AUTOSAR XML (schema 4-0-3)
package /ComponentTypes
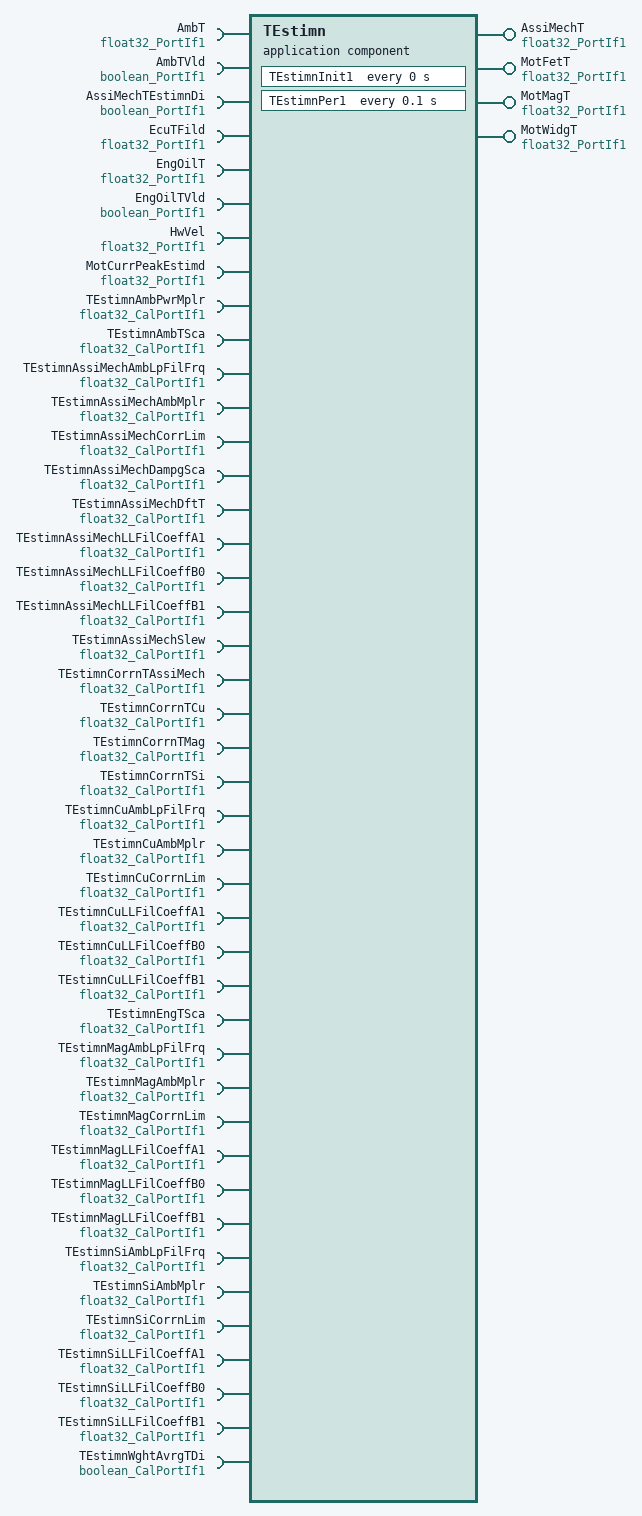
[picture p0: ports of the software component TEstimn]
  application sw component type TEstimn
    4 x provide port, all with nonqueued-sender-com-spec{data-element=Val, init-value=25}, provided-interface=float32_PortIf1:
      AssiMechT
      MotFetT
      MotMagT
      MotWidgT
    43 x require port:
      AmbT: nonqueued-receiver-com-spec{data-element=Val, filter=data-filter-type=ALWAYS, init-value=0}, required-interface=float32_PortIf1
      AmbTVld: nonqueued-receiver-com-spec{data-element=Logl, filter=data-filter-type=ALWAYS, init-value=0}, required-interface=boolean_PortIf1
      AssiMechTEstimnDi: nonqueued-receiver-com-spec{data-element=Logl, filter=data-filter-type=ALWAYS, init-value=0}, required-interface=boolean_PortIf1
      EcuTFild: nonqueued-receiver-com-spec{data-element=Val, filter=data-filter-type=ALWAYS, init-value=25}, required-interface=float32_PortIf1
      EngOilT: nonqueued-receiver-com-spec{data-element=Val, filter=data-filter-type=ALWAYS, init-value=0}, required-interface=float32_PortIf1
      EngOilTVld: nonqueued-receiver-com-spec{data-element=Logl, filter=data-filter-type=ALWAYS, init-value=0}, required-interface=boolean_PortIf1
      HwVel: nonqueued-receiver-com-spec{data-element=Val, filter=data-filter-type=ALWAYS, init-value=0}, required-interface=float32_PortIf1
      MotCurrPeakEstimd: nonqueued-receiver-com-spec{data-element=Val, filter=data-filter-type=ALWAYS, init-value=0}, required-interface=float32_PortIf1
      TEstimnAmbPwrMplr: parameter-require-com-spec{init-value=0.01, parameter=Val}, required-interface=float32_CalPortIf1
      TEstimnAmbTSca: parameter-require-com-spec{init-value=0.9, parameter=Val}, required-interface=float32_CalPortIf1
      TEstimnAssiMechAmbLpFilFrq: parameter-require-com-spec{init-value=0.024, parameter=Val}, required-interface=float32_CalPortIf1
      TEstimnAssiMechAmbMplr: parameter-require-com-spec{init-value=0.01, parameter=Val}, required-interface=float32_CalPortIf1
      TEstimnAssiMechCorrLim: parameter-require-com-spec{init-value=60, parameter=Val}, required-interface=float32_CalPortIf1
      TEstimnAssiMechDampgSca: parameter-require-com-spec{init-value=0.0001, parameter=Val}, required-interface=float32_CalPortIf1
      TEstimnAssiMechDftT: parameter-require-com-spec{init-value=50, parameter=Val}, required-interface=float32_CalPortIf1
      TEstimnAssiMechLLFilCoeffA1: parameter-require-com-spec{init-value=0.99996858, parameter=Val}, required-interface=float32_CalPortIf1
      TEstimnAssiMechLLFilCoeffB0: parameter-require-com-spec{init-value=0.4761987, parameter=Val}, required-interface=float32_CalPortIf1
      TEstimnAssiMechLLFilCoeffB1: parameter-require-com-spec{init-value=-0.4761673, parameter=Val}, required-interface=float32_CalPortIf1
      TEstimnAssiMechSlew: parameter-require-com-spec{init-value=1, parameter=Val}, required-interface=float32_CalPortIf1
      TEstimnCorrnTAssiMech: parameter-require-com-spec{init-value=0, parameter=Val}, required-interface=float32_CalPortIf1
      TEstimnCorrnTCu: parameter-require-com-spec{init-value=0, parameter=Val}, required-interface=float32_CalPortIf1
      TEstimnCorrnTMag: parameter-require-com-spec{init-value=0, parameter=Val}, required-interface=float32_CalPortIf1
      TEstimnCorrnTSi: parameter-require-com-spec{init-value=0, parameter=Val}, required-interface=float32_CalPortIf1
      TEstimnCuAmbLpFilFrq: parameter-require-com-spec{init-value=0.024, parameter=Val}, required-interface=float32_CalPortIf1
      TEstimnCuAmbMplr: parameter-require-com-spec{init-value=0.75, parameter=Val}, required-interface=float32_CalPortIf1
      TEstimnCuCorrnLim: parameter-require-com-spec{init-value=80, parameter=Val}, required-interface=float32_CalPortIf1
      TEstimnCuLLFilCoeffA1: parameter-require-com-spec{init-value=0.999943, parameter=Val}, required-interface=float32_CalPortIf1
      TEstimnCuLLFilCoeffB0: parameter-require-com-spec{init-value=0.86667, parameter=Val}, required-interface=float32_CalPortIf1
      TEstimnCuLLFilCoeffB1: parameter-require-com-spec{init-value=-0.866613, parameter=Val}, required-interface=float32_CalPortIf1
      TEstimnEngTSca: parameter-require-com-spec{init-value=0.1, parameter=Val}, required-interface=float32_CalPortIf1
      TEstimnMagAmbLpFilFrq: parameter-require-com-spec{init-value=0.024, parameter=Val}, required-interface=float32_CalPortIf1
      TEstimnMagAmbMplr: parameter-require-com-spec{init-value=0.01, parameter=Val}, required-interface=float32_CalPortIf1
      TEstimnMagCorrnLim: parameter-require-com-spec{init-value=60, parameter=Val}, required-interface=float32_CalPortIf1
      TEstimnMagLLFilCoeffA1: parameter-require-com-spec{init-value=0.999962, parameter=Val}, required-interface=float32_CalPortIf1
      TEstimnMagLLFilCoeffB0: parameter-require-com-spec{init-value=0.571437, parameter=Val}, required-interface=float32_CalPortIf1
      TEstimnMagLLFilCoeffB1: parameter-require-com-spec{init-value=-0.571399, parameter=Val}, required-interface=float32_CalPortIf1
      TEstimnSiAmbLpFilFrq: parameter-require-com-spec{init-value=0.024, parameter=Val}, required-interface=float32_CalPortIf1
      TEstimnSiAmbMplr: parameter-require-com-spec{init-value=0, parameter=Val}, required-interface=float32_CalPortIf1
      TEstimnSiCorrnLim: parameter-require-com-spec{init-value=60, parameter=Val}, required-interface=float32_CalPortIf1
      TEstimnSiLLFilCoeffA1: parameter-require-com-spec{init-value=0.999889, parameter=Val}, required-interface=float32_CalPortIf1
      TEstimnSiLLFilCoeffB0: parameter-require-com-spec{init-value=1.68568, parameter=Val}, required-interface=float32_CalPortIf1
      TEstimnSiLLFilCoeffB1: parameter-require-com-spec{init-value=-1.68556, parameter=Val}, required-interface=float32_CalPortIf1
      TEstimnWghtAvrgTDi: parameter-require-com-spec{init-value=0, parameter=Logl}, required-interface=boolean_CalPortIf1
    behavior TEstimn_InternalBehavior
      ar-typed-per-instance-memorys:
        26 x data, all with sw-calibration-access=READ-ONLY:
          AmbTVldPrev: type=boolean
          AssiMechFilLp: type=FilLpRec1
          AssiMechTEstimnPrev: type=float32
          AssiMechTInitEna: type=boolean
          AssiMechTSlewLimPrev: type=float32
          CuFilLp: type=FilLpRec1
          CuTEstimnPrev: type=float32
          dTEstimnAmbPwr: type=float32
          dTEstimnAssiMechCorrn: type=float32
          dTEstimnAssiMechDampgSca: type=float32
          dTEstimnAssiMechFil: type=float32
          dTEstimnAssiMechLLFil: type=float32
          dTEstimnCuCorrn: type=float32
          dTEstimnCuLLFil: type=float32
          dTEstimnMagCorrn: type=float32
          dTEstimnMagLLFil: type=float32
          dTEstimnScadAmbT: type=float32
          dTEstimnScadEngT: type=float32
          dTEstimnSiCorrn: type=float32
          dTEstimnSiLLFilv: type=float32
          dTEstimnWghtAvrgT: type=float32
          EngOilTVldPrev: type=boolean
          MagFilLp: type=FilLpRec1
          MagTEstimnPrev: type=float32
          SiFilLp: type=FilLpRec1
          SiTEstimnPrev: type=float32
      timing event TEstimn_InitEvent: start-on-event=TEstimnInit1, period=0
      timing event TMT_TEstimnPer1: start-on-event=TEstimnPer1, period=0.1
      runnable TEstimnInit1
        data-receive-point-by-arguments:
          5 x access:
            REC_AmbT_Val: accessed-variable=AmbT.Val
            REC_AmbTVld_Logl: accessed-variable=AmbTVld.Logl
            REC_EcuTFild_Val: accessed-variable=EcuTFild.Val
            REC_EngOilT_Val: accessed-variable=EngOilT.Val
            REC_EngOilTVld_Logl: accessed-variable=EngOilTVld.Logl
        data-send-points:
          4 x access:
            SEND_AssiMechT_Val: accessed-variable=AssiMechT.Val
            SEND_MotFetT_Val: accessed-variable=MotFetT.Val
            SEND_MotMagT_Val: accessed-variable=MotMagT.Val
            SEND_MotWidgT_Val: accessed-variable=MotWidgT.Val
      runnable TEstimnPer1
        data-receive-point-by-arguments:
          8 x access:
            REC_AmbT_Val: accessed-variable=AmbT.Val
            REC_AmbTVld_Logl: accessed-variable=AmbTVld.Logl
            REC_AssiMechTEstimnDi_Logl: accessed-variable=AssiMechTEstimnDi.Logl
            REC_EcuTFild_Val: accessed-variable=EcuTFild.Val
            REC_EngOilT_Val: accessed-variable=EngOilT.Val
            REC_EngOilTVld_Logl: accessed-variable=EngOilTVld.Logl
            REC_HwVel_Val: accessed-variable=HwVel.Val
            REC_MotCurrPeakEstimd_Val: accessed-variable=MotCurrPeakEstimd.Val
        data-send-points:
          4 x access:
            SEND_AssiMechT_Val: accessed-variable=AssiMechT.Val
            SEND_MotFetT_Val: accessed-variable=MotFetT.Val
            SEND_MotMagT_Val: accessed-variable=MotMagT.Val
            SEND_MotWidgT_Val: accessed-variable=MotWidgT.Val
  swc implementation TEstimn_Implementation: behavior=TEstimn_InternalBehavior
    code-descriptors:
      code Default: artifact-descriptors=autosar-engineering-object={short-label=Default, category=SWSRC}
